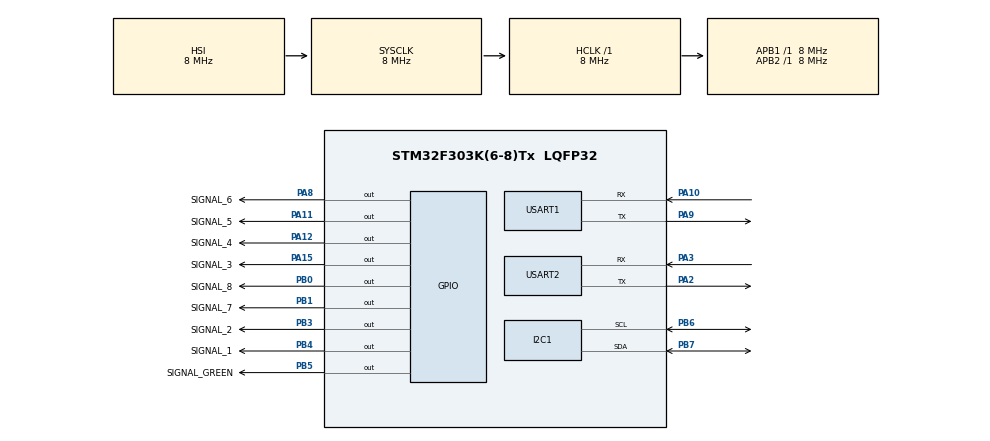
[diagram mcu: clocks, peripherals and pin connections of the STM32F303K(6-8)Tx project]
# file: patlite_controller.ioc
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FREERTOS.Tasks01=defaultTask,0,128,StartDefaultTask,Default
I2C1.Timing=0x2000090E
Mcu.Family=STM32F3
Mcu.Name=STM32F303K(6-8)Tx
Mcu.Package=LQFP32
NVIC.PriorityGroup=NVIC_PRIORITYGROUP_4
PA10.Mode=Asynchronous
PA10.Signal=USART1_RX
PA11.GPIO_Label=SIGNAL_5
PA11.GPIO_PuPd=GPIO_PULLDOWN
PA11.Signal=GPIO_Output
PA12.GPIO_Label=SIGNAL_4
PA12.GPIO_PuPd=GPIO_PULLDOWN
PA12.Signal=GPIO_Output
PA13.GPIO_Label=SWDIO
PA13.Mode=Serial_Wire
PA13.Signal=SYS_JTMS-SWDIO
PA14.GPIO_Label=SWDCLK
PA14.Mode=Serial_Wire
PA14.Signal=SYS_JTCK-SWCLK
PA15.GPIO_Label=SIGNAL_3
PA15.GPIO_PuPd=GPIO_PULLDOWN
PA15.Signal=GPIO_Output
PA2.Mode=Asynchronous
PA2.Signal=USART2_TX
PA3.Mode=Asynchronous
PA3.Signal=USART2_RX
PA4.Signal=SPI1_NSS
PA5.Signal=SPI1_SCK
PA6.Signal=SPI1_MISO
PA7.Signal=SPI1_MOSI
PA8.GPIO_Label=SIGNAL_6
PA8.GPIO_PuPd=GPIO_PULLDOWN
PA8.Signal=GPIO_Output
PA9.Mode=Asynchronous
PA9.Signal=USART1_TX
PB0.GPIO_Label=SIGNAL_8
PB0.GPIO_PuPd=GPIO_PULLDOWN
PB0.Signal=GPIO_Output
PB1.GPIO_Label=SIGNAL_7
PB1.GPIO_PuPd=GPIO_PULLDOWN
PB1.Signal=GPIO_Output
PB3.GPIO_Label=SIGNAL_2
PB3.GPIO_PuPd=GPIO_PULLDOWN
PB3.Signal=GPIO_Output
PB4.GPIO_Label=SIGNAL_1
PB4.GPIO_PuPd=GPIO_PULLDOWN
PB4.Signal=GPIO_Output
PB5.GPIO_Label=SIGNAL_GREEN
PB5.GPIO_PuPd=GPIO_PULLDOWN
PB5.Signal=GPIO_Output
PB6.Mode=I2C
PB6.Signal=I2C1_SCL
PB7.Mode=I2C
PB7.Signal=I2C1_SDA
ProjectManager.HeapSize=0x200
ProjectManager.StackSize=0x400
ProjectManager.TargetToolchain=SW4STM32
RCC.AHBFreq_Value=8000000
RCC.APB1Freq_Value=8000000
RCC.APB2Freq_Value=8000000
RCC.CortexFreq_Value=8000000
RCC.HSE_VALUE=8000000
RCC.HSI_VALUE=8000000
RCC.SYSCLKFreq_VALUE=8000000
VP_FREERTOS_VS_ENABLE.Mode=Enabled
board=patlite_controller

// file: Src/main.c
/**
  ******************************************************************************
  * File Name          : main.c
  * Description        : Main program body
  ******************************************************************************
  *
  * Copyright (c) 2016 STMicroelectronics International N.V.
  * All rights reserved.
  *
  * Redistribution and use in source and binary forms, with or without
  * modification, are permitted, provided that the following conditions are met:
  *
  * 1. Redistribution of source code must retain the above copyright notice,
  *    this list of conditions and the following disclaimer.
  * 2. Redistributions in binary form must reproduce the above copyright notice,
  *    this list of conditions and the following disclaimer in the documentation
  *    and/or other materials provided with the distribution.
  * 3. Neither the name of STMicroelectronics nor the names of other
  *    contributors to this software may be used to endorse or promote products
  *    derived from this software without specific written permission.
  * 4. This software, including modifications and/or derivative works of this
  *    software, must execute solely and exclusively on microcontroller or
  *    microprocessor devices manufactured by or for STMicroelectronics.
  * 5. Redistribution and use of this software other than as permitted under
  *    this license is void and will automatically terminate your rights under
  *    this license.
  *
  * THIS SOFTWARE IS PROVIDED BY STMICROELECTRONICS AND CONTRIBUTORS "AS IS"
  * AND ANY EXPRESS, IMPLIED OR STATUTORY WARRANTIES, INCLUDING, BUT NOT
  * LIMITED TO, THE IMPLIED WARRANTIES OF MERCHANTABILITY, FITNESS FOR A
  * PARTICULAR PURPOSE AND NON-INFRINGEMENT OF THIRD PARTY INTELLECTUAL PROPERTY
  * RIGHTS ARE DISCLAIMED TO THE FULLEST EXTENT PERMITTED BY LAW. IN NO EVENT
  * SHALL STMICROELECTRONICS OR CONTRIBUTORS BE LIABLE FOR ANY DIRECT, INDIRECT,
  * INCIDENTAL, SPECIAL, EXEMPLARY, OR CONSEQUENTIAL DAMAGES (INCLUDING, BUT NOT
  * LIMITED TO, PROCUREMENT OF SUBSTITUTE GOODS OR SERVICES; LOSS OF USE, DATA,
  * OR PROFITS; OR BUSINESS INTERRUPTION) HOWEVER CAUSED AND ON ANY THEORY OF
  * LIABILITY, WHETHER IN CONTRACT, STRICT LIABILITY, OR TORT (INCLUDING
  * NEGLIGENCE OR OTHERWISE) ARISING IN ANY WAY OUT OF THE USE OF THIS SOFTWARE,
  * EVEN IF ADVISED OF THE POSSIBILITY OF SUCH DAMAGE.
  *
  ******************************************************************************
  */
#include "main.h"
#include "stm32f3xx_hal.h"
#include "cmsis_os.h"

/* USER CODE BEGIN Includes */
#include "patlite.h"
/* USER CODE END Includes */

I2C_HandleTypeDef hi2c1;

UART_HandleTypeDef huart1;
UART_HandleTypeDef huart2;

osThreadId defaultTaskHandle;
osThreadId signalControlTaskHandle;

/* USER CODE BEGIN PV */
/* Private variables ---------------------------------------------------------*/

/* USER CODE END PV */

void SystemClock_Config(void);
void Error_Handler(void);
static void MX_GPIO_Init(void);
static void MX_USART2_UART_Init(void);
static void MX_USART1_UART_Init(void);
static void MX_I2C1_Init(void);
void StartDefaultTask(void const *argument);

/* USER CODE BEGIN PFP */
/* Private function prototypes -----------------------------------------------*/

/* USER CODE END PFP */

/* USER CODE BEGIN 0 */
void _init() {}
/* USER CODE END 0 */

int main(void)
{

    /* MCU Configuration----------------------------------------------------------*/

    /* Reset of all peripherals, Initializes the Flash interface and the Systick. */
    HAL_Init();

    /* Configure the system clock */
    SystemClock_Config();

    /* Initialize all configured peripherals */
    MX_GPIO_Init();
    MX_USART2_UART_Init();
    MX_USART1_UART_Init();
    MX_I2C1_Init();

    /* Create the thread(s) */
    /* definition and creation of defaultTask */
    osThreadDef(defaultTask, StartDefaultTask, osPriorityNormal, 0, 128);
    defaultTaskHandle = osThreadCreate(osThread(defaultTask), NULL);

    /* USER CODE BEGIN RTOS_THREADS */
    osThreadDef(signalControlTask, SignalControlTask, osPriorityNormal, 0, 128);
    signalControlTaskHandle = osThreadCreate(osThread(signalControlTask), NULL);
    /* USER CODE END RTOS_THREADS */

    /* Start scheduler */
    osKernelStart();

    /* We should never get here as control is now taken by the scheduler */

    /* Infinite loop */
    while (1)
    {

    }
}

/** System Clock Configuration
*/
void SystemClock_Config(void)
{

    RCC_OscInitTypeDef RCC_OscInitStruct;
    RCC_ClkInitTypeDef RCC_ClkInitStruct;
    RCC_PeriphCLKInitTypeDef PeriphClkInit;

    /**Initializes the CPU, AHB and APB busses clocks
    */
    RCC_OscInitStruct.OscillatorType = RCC_OSCILLATORTYPE_HSI;
    RCC_OscInitStruct.HSIState = RCC_HSI_ON;
    RCC_OscInitStruct.HSICalibrationValue = 16;
    RCC_OscInitStruct.PLL.PLLState = RCC_PLL_NONE;
    if (HAL_RCC_OscConfig(&RCC_OscInitStruct) != HAL_OK)
    {
        Error_Handler();
    }

    /**Initializes the CPU, AHB and APB busses clocks
    */
    RCC_ClkInitStruct.ClockType = RCC_CLOCKTYPE_HCLK | RCC_CLOCKTYPE_SYSCLK | RCC_CLOCKTYPE_PCLK1 | RCC_CLOCKTYPE_PCLK2;
    RCC_ClkInitStruct.SYSCLKSource = RCC_SYSCLKSOURCE_HSI;
    RCC_ClkInitStruct.AHBCLKDivider = RCC_SYSCLK_DIV1;
    RCC_ClkInitStruct.APB1CLKDivider = RCC_HCLK_DIV1;
    RCC_ClkInitStruct.APB2CLKDivider = RCC_HCLK_DIV1;

    if (HAL_RCC_ClockConfig(&RCC_ClkInitStruct, FLASH_LATENCY_0) != HAL_OK)
    {
        Error_Handler();
    }

    PeriphClkInit.PeriphClockSelection = RCC_PERIPHCLK_USART1 | RCC_PERIPHCLK_I2C1;
    PeriphClkInit.Usart1ClockSelection = RCC_USART1CLKSOURCE_PCLK1;
    PeriphClkInit.I2c1ClockSelection = RCC_I2C1CLKSOURCE_HSI;
    if (HAL_RCCEx_PeriphCLKConfig(&PeriphClkInit) != HAL_OK)
    {
        Error_Handler();
    }

    /**Configure the Systick interrupt time
    */
    HAL_SYSTICK_Config(HAL_RCC_GetHCLKFreq() / 1000);

    /**Configure the Systick
    */
    HAL_SYSTICK_CLKSourceConfig(SYSTICK_CLKSOURCE_HCLK);

    /* SysTick_IRQn interrupt configuration */
    HAL_NVIC_SetPriority(SysTick_IRQn, 15, 0);
}

/* I2C1 init function */
static void MX_I2C1_Init(void)
{

    hi2c1.Instance = I2C1;
    hi2c1.Init.Timing = 0x2000090E;
    hi2c1.Init.OwnAddress1 = 0;
    hi2c1.Init.AddressingMode = I2C_ADDRESSINGMODE_7BIT;
    hi2c1.Init.DualAddressMode = I2C_DUALADDRESS_DISABLE;
    hi2c1.Init.OwnAddress2 = 0;
    hi2c1.Init.OwnAddress2Masks = I2C_OA2_NOMASK;
    hi2c1.Init.GeneralCallMode = I2C_GENERALCALL_DISABLE;
    hi2c1.Init.NoStretchMode = I2C_NOSTRETCH_DISABLE;
    if (HAL_I2C_Init(&hi2c1) != HAL_OK)
    {
        Error_Handler();
    }

    /**Configure Analogue filter
    */
    if (HAL_I2CEx_ConfigAnalogFilter(&hi2c1, I2C_ANALOGFILTER_ENABLE) != HAL_OK)
    {
        Error_Handler();
    }
}

/* USART1 init function */
static void MX_USART1_UART_Init(void)
{

    huart1.Instance = USART1;
    huart1.Init.BaudRate = 38400;
    huart1.Init.WordLength = UART_WORDLENGTH_7B;
    huart1.Init.StopBits = UART_STOPBITS_1;
    huart1.Init.Parity = UART_PARITY_NONE;
    huart1.Init.Mode = UART_MODE_TX_RX;
    huart1.Init.HwFlowCtl = UART_HWCONTROL_NONE;
    huart1.Init.OverSampling = UART_OVERSAMPLING_16;
    huart1.Init.OneBitSampling = UART_ONE_BIT_SAMPLE_DISABLE;
    huart1.AdvancedInit.AdvFeatureInit = UART_ADVFEATURE_NO_INIT;
    if (HAL_UART_Init(&huart1) != HAL_OK)
    {
        Error_Handler();
    }
}

/* USART2 init function */
static void MX_USART2_UART_Init(void)
{

    huart2.Instance = USART2;
    huart2.Init.BaudRate = 38400;
    huart2.Init.WordLength = UART_WORDLENGTH_7B;
    huart2.Init.StopBits = UART_STOPBITS_1;
    huart2.Init.Parity = UART_PARITY_NONE;
    huart2.Init.Mode = UART_MODE_TX_RX;
    huart2.Init.HwFlowCtl = UART_HWCONTROL_NONE;
    huart2.Init.OverSampling = UART_OVERSAMPLING_16;
    huart2.Init.OneBitSampling = UART_ONE_BIT_SAMPLE_DISABLE;
    huart2.AdvancedInit.AdvFeatureInit = UART_ADVFEATURE_NO_INIT;
    if (HAL_UART_Init(&huart2) != HAL_OK)
    {
        Error_Handler();
    }
}

/** Configure pins
     PA4   ------> SPI1_NSS
     PA5   ------> SPI1_SCK
     PA6   ------> SPI1_MISO
     PA7   ------> SPI1_MOSI
*/
static void MX_GPIO_Init(void)
{

    GPIO_InitTypeDef GPIO_InitStruct;

    /* GPIO Ports Clock Enable */
    __HAL_RCC_GPIOA_CLK_ENABLE();
    __HAL_RCC_GPIOB_CLK_ENABLE();

    /*Configure GPIO pins : PA4 PA5 PA6 PA7 */
    GPIO_InitStruct.Pin = GPIO_PIN_4 | GPIO_PIN_5 | GPIO_PIN_6 | GPIO_PIN_7;
    GPIO_InitStruct.Mode = GPIO_MODE_AF_PP;
    GPIO_InitStruct.Pull = GPIO_NOPULL;
    GPIO_InitStruct.Speed = GPIO_SPEED_FREQ_HIGH;
    GPIO_InitStruct.Alternate = GPIO_AF5_SPI1;
    HAL_GPIO_Init(GPIOA, &GPIO_InitStruct);

    /*Configure GPIO pins : SIGNAL_8_Pin SIGNAL_7_Pin SIGNAL_2_Pin SIGNAL_1_Pin
                           SIGNAL_GREEN_Pin */
    GPIO_InitStruct.Pin = SIGNAL_8_Pin | SIGNAL_7_Pin | SIGNAL_2_Pin | SIGNAL_1_Pin | SIGNAL_GREEN_Pin;
    GPIO_InitStruct.Mode = GPIO_MODE_OUTPUT_PP;
    GPIO_InitStruct.Pull = GPIO_PULLDOWN;
    GPIO_InitStruct.Speed = GPIO_SPEED_FREQ_LOW;
    HAL_GPIO_Init(GPIOB, &GPIO_InitStruct);

    /*Configure GPIO pins : SIGNAL_6_Pin SIGNAL_5_Pin SIGNAL_4_Pin SIGNAL_3_Pin */
    GPIO_InitStruct.Pin = SIGNAL_6_Pin | SIGNAL_5_Pin | SIGNAL_4_Pin | SIGNAL_3_Pin;
    GPIO_InitStruct.Mode = GPIO_MODE_OUTPUT_PP;
    GPIO_InitStruct.Pull = GPIO_PULLDOWN;
    GPIO_InitStruct.Speed = GPIO_SPEED_FREQ_LOW;
    HAL_GPIO_Init(GPIOA, &GPIO_InitStruct);

    /*Configure GPIO pin Output Level */
    HAL_GPIO_WritePin(GPIOB, SIGNAL_8_Pin | SIGNAL_7_Pin | SIGNAL_2_Pin | SIGNAL_1_Pin | SIGNAL_GREEN_Pin, GPIO_PIN_RESET);

    /*Configure GPIO pin Output Level */
    HAL_GPIO_WritePin(GPIOA, SIGNAL_6_Pin | SIGNAL_5_Pin | SIGNAL_4_Pin | SIGNAL_3_Pin, GPIO_PIN_RESET);
}

/* StartDefaultTask function */
void StartDefaultTask(void const *argument)
{

    /* USER CODE BEGIN 5 */
    /* Infinite loop */
    for (;;)
    {
        osDelay(1000);
    }
    /* USER CODE END 5 */
}

void Error_Handler(void)
{
    while (1)
    {
    }
}

/************************ (C) COPYRIGHT STMicroelectronics *****END OF FILE****/
